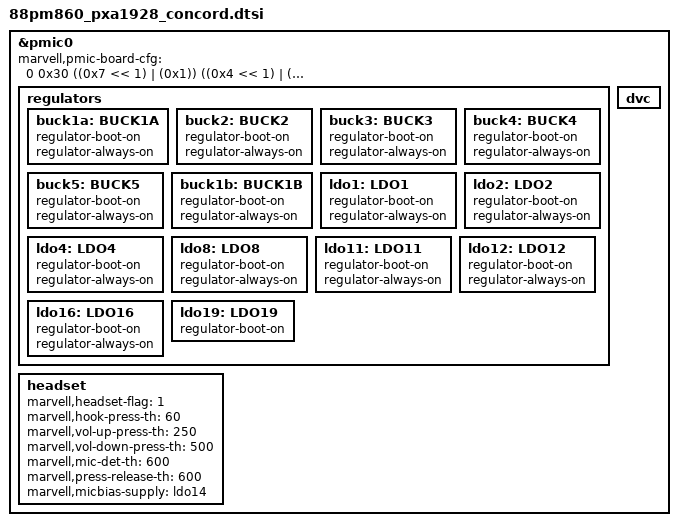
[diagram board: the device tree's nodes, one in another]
/*
 * Copyright (C) 2014 Marvell
 * Yi Zhang <yizhang@marvell.com>
 * 88pm860 description for eden_concord
 */

#include "88pm8xx.dtsi"
#include "88pm860.dtsi"

&pmic0 {
	/*
	 * board specific register configuration
	 * marvell,pmic-board-cfg = <page reg mask data>;
	 */
	marvell,pmic-board-cfg = <
		/*
		 * Set GPIO0 to 32KHz output
		 */
		0
		0x30
		((0x7 << 1) | (0x1))
		((0x4 << 1) | (0x1))

		/*
		 * Set vcc_main sleep voltage to 0.7v
		 */
		1
		0x30
		0x7f
		0x08
		>;

	regulators {
		buck1a: BUCK1A {regulator-boot-on;regulator-always-on;};
		buck2: BUCK2 {regulator-boot-on;regulator-always-on;};
		buck3: BUCK3 {regulator-boot-on;regulator-always-on;};
		buck4: BUCK4 {regulator-boot-on;regulator-always-on;};
		buck5: BUCK5 {regulator-boot-on;regulator-always-on;};
		buck1b: BUCK1B {regulator-boot-on;regulator-always-on;};

		ldo1: LDO1 {regulator-boot-on;regulator-always-on;};
		ldo2: LDO2 {regulator-boot-on;regulator-always-on;};
		ldo4: LDO4 {regulator-boot-on;regulator-always-on;};
		ldo8: LDO8 {regulator-boot-on;regulator-always-on;};
		ldo11: LDO11 {regulator-boot-on;regulator-always-on;};
		ldo12: LDO12 {regulator-boot-on;regulator-always-on;};
		ldo16: LDO16 {regulator-boot-on;regulator-always-on;};
		ldo19: LDO19 {regulator-boot-on;};
	};

	headset {
		marvell,headset-flag = <1>;
		marvell,hook-press-th = <60>;
		marvell,vol-up-press-th = <250>;
		marvell,vol-down-press-th = <500>;
		marvell,mic-det-th = <600>;
		marvell,press-release-th = <600>;
		marvell,micbias-supply = <&ldo14>;
		status = "okay";
	};
	dvc {
		status = "okay";
	};
};
